# M460 register map
File version: 1.0
Registers are 32-bit, read-write, reset 0x0 unless marked. A register's access mark holds for its fields unless they carry their own. Offsets are from the block's base; [hi:lo] are bit positions; {n}, {i} and the like mark numbered series.

## PA — GPIO Register Map
Base 0x40004800
{0x0+4i} PA{i}_PDIO (reset mask 0xFFFFFFF0) (i=0..15) — GPIO PA.n Pin Data Input/Output Register
  [0] PDIO — GPIO Px.n Pin Data Input/Output. Writing this bit can control one GPIO pin output value.
    0=Corresponding GPIO pin set to low; 1=Corresponding GPIO pin set to high

## PB — GPIO Register Map
Base 0x40004840
{0x0+4i} PB{i}_PDIO (reset mask 0xFFFFFFF0) (i=0..15) — GPIO PB.n Pin Data Input/Output Register
  [0] PDIO — GPIO Px.n Pin Data Input/Output. Writing this bit can control one GPIO pin output value.
    0=Corresponding GPIO pin set to low; 1=Corresponding GPIO pin set to high

## PC — GPIO Register Map
Base 0x40004880
{0x0+4i} PC{i}_PDIO (reset mask 0xFFFFFFF0) (i=0..14) — GPIO PC.n Pin Data Input/Output Register
  [0] PDIO — GPIO Px.n Pin Data Input/Output. Writing this bit can control one GPIO pin output value.
    0=Corresponding GPIO pin set to low; 1=Corresponding GPIO pin set to high

## PD — GPIO Register Map
Base 0x400048C0
{0x0+4i} PD{i}_PDIO (reset mask 0xFFFFFFF0) (i=0..14) — GPIO PD.n Pin Data Input/Output Register
  [0] PDIO — GPIO Px.n Pin Data Input/Output. Writing this bit can control one GPIO pin output value.
    0=Corresponding GPIO pin set to low; 1=Corresponding GPIO pin set to high

## PE — GPIO Register Map
Base 0x40004900
{0x0+4i} PE{i}_PDIO (reset mask 0xFFFFFFF0) (i=0..15) — GPIO PE.n Pin Data Input/Output Register
  [0] PDIO — GPIO Px.n Pin Data Input/Output. Writing this bit can control one GPIO pin output value.
    0=Corresponding GPIO pin set to low; 1=Corresponding GPIO pin set to high

## PF — GPIO Register Map
Base 0x40004940
{0x0+4i} PF{i}_PDIO (reset mask 0xFFFFFFF0) (i=0..11) — GPIO PF.n Pin Data Input/Output Register
  [0] PDIO — GPIO Px.n Pin Data Input/Output. Writing this bit can control one GPIO pin output value.
    0=Corresponding GPIO pin set to low; 1=Corresponding GPIO pin set to high

## PG — GPIO Register Map
Base 0x40004980
{0x0+4i} PG{i}_PDIO (reset mask 0xFFFFFFF0) (i=0..15) — GPIO PG.n Pin Data Input/Output Register
  [0] PDIO — GPIO Px.n Pin Data Input/Output. Writing this bit can control one GPIO pin output value.
    0=Corresponding GPIO pin set to low; 1=Corresponding GPIO pin set to high

## PH — GPIO Register Map
Base 0x400049C0
{0x0+4i} PH{i}_PDIO (reset mask 0xFFFFFFF0) (i=0..15) — GPIO PH.n Pin Data Input/Output Register
  [0] PDIO — GPIO Px.n Pin Data Input/Output. Writing this bit can control one GPIO pin output value.
    0=Corresponding GPIO pin set to low; 1=Corresponding GPIO pin set to high

## PI — GPIO Register Map
Base 0x40004A00
{0x0+4i} PI{i}_PDIO (reset mask 0xFFFFFFF0) (i=6..15) — GPIO PI.n Pin Data Input/Output Register
  [0] PDIO — GPIO Px.n Pin Data Input/Output. Writing this bit can control one GPIO pin output value.
    0=Corresponding GPIO pin set to low; 1=Corresponding GPIO pin set to high

## PJ — GPIO Register Map
Base 0x40004A40
{0x0+4i} PJ{i}_PDIO (reset mask 0xFFFFFFF0) (i=0..13) — GPIO PJ.n Pin Data Input/Output Register
  [0] PDIO — GPIO Px.n Pin Data Input/Output. Writing this bit can control one GPIO pin output value.
    0=Corresponding GPIO pin set to low; 1=Corresponding GPIO pin set to high

## WWDT — WWDT Register Map
Base 0x40040100
0x00 WWDT_RLDCNT wo — WWDT Reload Counter Register
  [31:0] RLDCNT — WWDT Reload Counter Register. Writing 0x00005AA5 to this register will reload the WWDT counter value to 0x3F. Note: User can only write WWDT_RLDCNT register to reload WWDT counter value when current WWDT counter value between 0 and CMPDAT (WWDT_CTL[21:16]). If user writes WWDT_RLDCNT when current WWDT counter value is larger than CMPDAT, WWDT reset signal will be generated immediately.
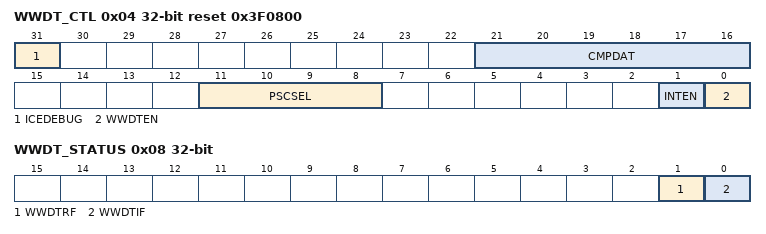
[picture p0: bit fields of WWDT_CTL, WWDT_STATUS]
0x04 WWDT_CTL reset 0x3F0800 — WWDT Control Register
  [31] ICEDEBUG — ICE Debug Mode Acknowledge Disable Bit. WWDT down counter will keep going no matter CPU is held by ICE or not.
    0=ICE debug mode acknowledgement effects WWDT counting; 1=ICE debug mode acknowledgement Disabled
  [21:16] CMPDAT — WWDT Window Compare. Set this register to adjust the valid reload window. Note: User can only write WWDT_RLDCNT register to reload WWDT counter value when current WWDT counter value between 0 and CMPDAT. If user writes WWDT_RLDCNT register when current WWDT counter value larger than CMPDAT, WWDT reset signal will generate immediately.
  [11:8] PSCSEL — WWDT Counter Prescale Period Selection
    0=Pre-scale is 1; Max time-out period is 1 * 64 * WWDT_CLK; 1=Pre-scale is 2; Max time-out period is 2 * 64 * WWDT_CLK; 2=Pre-scale is 4; Max time-out period is 4 * 64 * WWDT_CLK; 3=Pre-scale is 8; Max time-out period is 8 * 64 * WWDT_CLK; 4=Pre-scale is 16; Max time-out period is 16 * 64 * WWDT_CLK; 5=Pre-scale is 32; Max time-out period is 32 * 64 * WWDT_CLK; 6=Pre-scale is 64; Max time-out period is 64 * 64 * WWDT_CLK; 7=Pre-scale is 128; Max time-out period is 128 * 64 * WWDT_CLK; 8=Pre-scale is 192; Max time-out period is 192 * 64 * WWDT_CLK; 9=Pre-scale is 256; Max time-out period is 256 * 64 * WWDT_CLK; 10=Pre-scale is 384; Max time-out period is 384 * 64 * WWDT_CLK; 11=Pre-scale is 512; Max time-out period is 512 * 64 * WWDT_CLK; 12=Pre-scale is 768; Max time-out period is 768 * 64 * WWDT_CLK; 13=Pre-scale is 1024; Max time-out period is 1024 * 64 * WWDT_CLK; 14=Pre-scale is 1536; Max time-out period is 1536 * 64 * WWDT_CLK; 15=Pre-scale is 2048; Max time-out period is 2048 * 64 * WWDT_CLK
  [1] INTEN — WWDT Interrupt Enable Bit. If this bit is enabled, the WWDT counter compare match interrupt signal is generated and inform to CPU.
    0=WWDT counter compare match interrupt Disabled; 1=WWDT counter compare match interrupt Enabled
  [0] WWDTEN — WWDT Enable Bit
    0=WWDT counter is stopped; 1=Enable WWDT counter starts counting
0x08 WWDT_STATUS
  [1] WWDTRF — WWDT Timer-out Reset Flag. This bit indicates the system has been reset by WWDT time-out reset or not. Note: This bit is cleared by writing 1 to it.
    0=WWDT time-out reset did not occur; 1=WWDT time-out reset occurred
  [0] WWDTIF — WWDT Compare Match Interrupt Flag. This bit indicates the interrupt flag status of WWDT while WWDT counter value matches CMPDAT (WWDT_CTL[21:16]). Note: This bit is cleared by writing 1 to it.
    0=No effect; 1=WWDT counter value matches CMPDAT
0x0C WWDT_CNT ro reset 0x3F — WWDT Counter Value Register
  [5:0] CNTDAT — WWDT Counter Value. CNTDAT will be updated continuously to monitor 6-bit WWDT down counter value.
